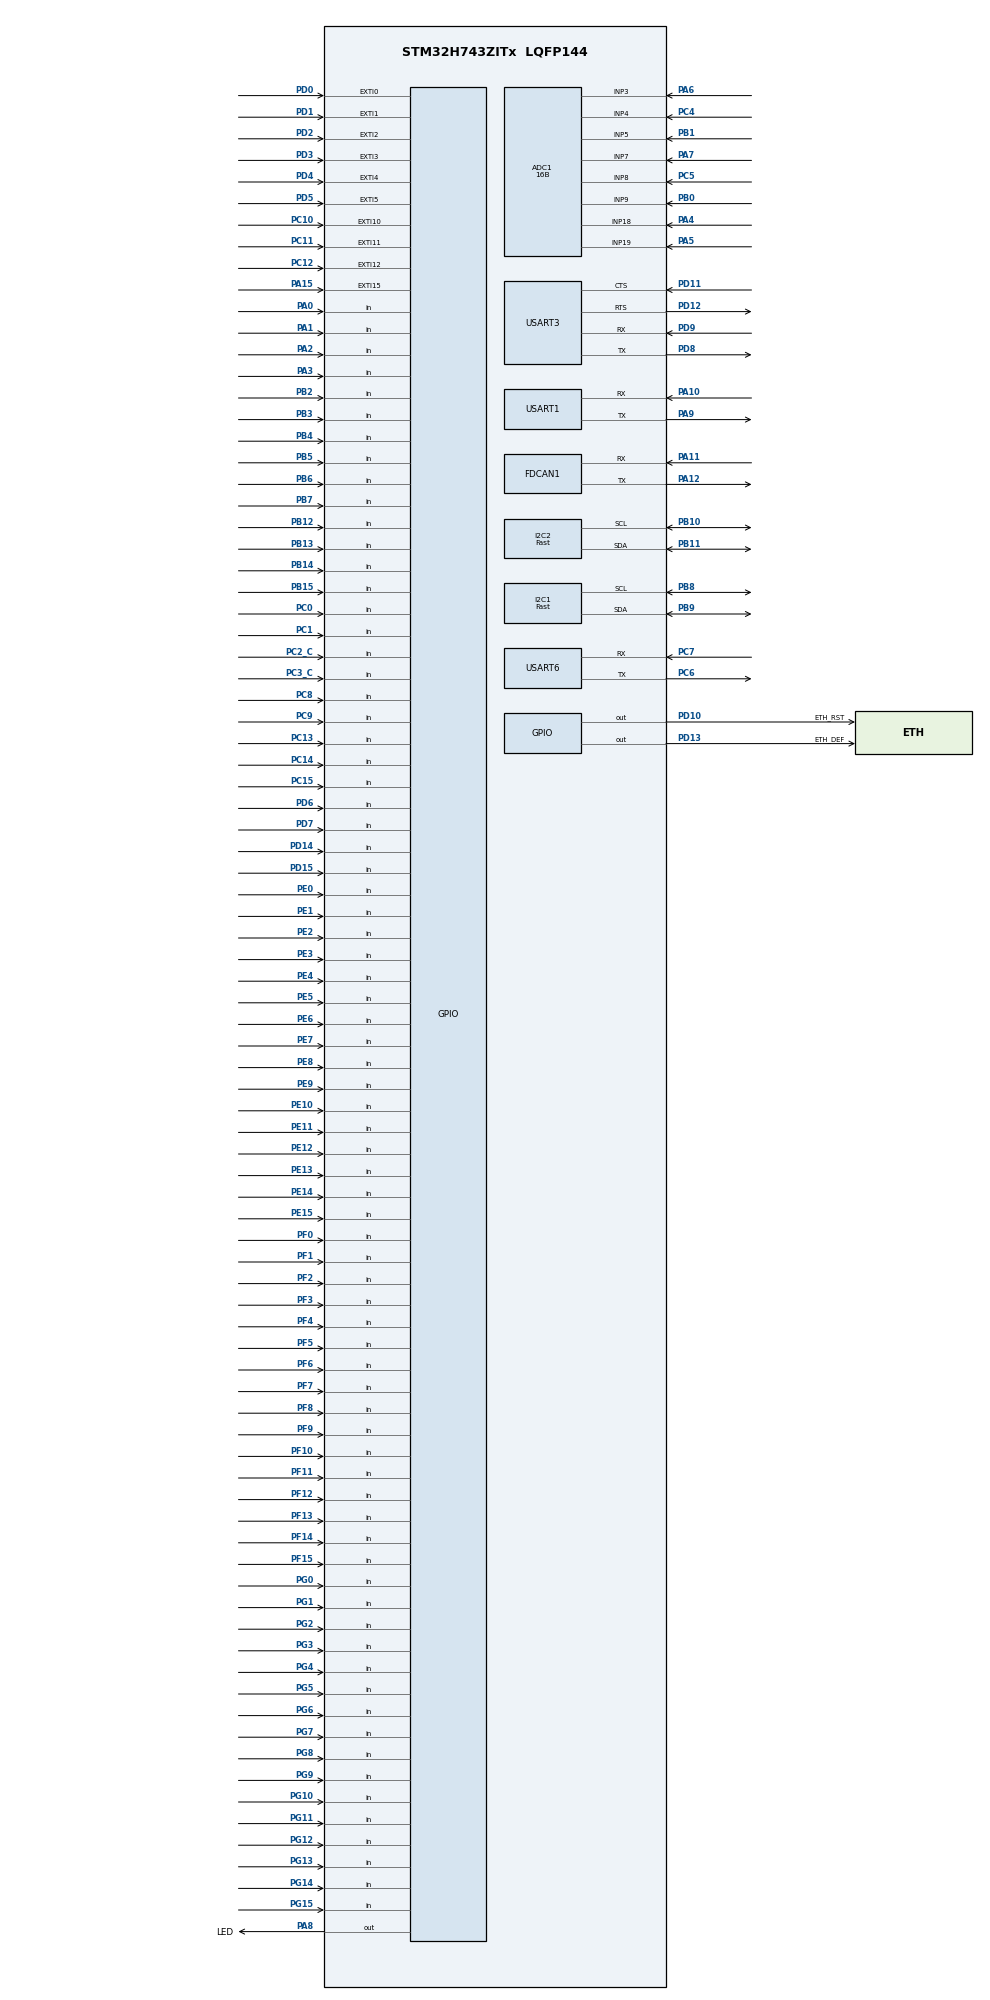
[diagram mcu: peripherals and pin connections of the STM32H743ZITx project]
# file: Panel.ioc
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ADC1.Channel-1\#ChannelRegularConversion=ADC_CHANNEL_18
ADC1.Channel-2\#ChannelRegularConversion=ADC_CHANNEL_19
ADC1.Channel-3\#ChannelRegularConversion=ADC_CHANNEL_3
ADC1.Channel-4\#ChannelRegularConversion=ADC_CHANNEL_7
ADC1.Channel-5\#ChannelRegularConversion=ADC_CHANNEL_4
ADC1.Channel-6\#ChannelRegularConversion=ADC_CHANNEL_8
ADC1.Channel-7\#ChannelRegularConversion=ADC_CHANNEL_9
ADC1.Channel-8\#ChannelRegularConversion=ADC_CHANNEL_5
ADC1.ClockPrescaler=ADC_CLOCK_ASYNC_DIV64
ADC1.ContinuousConvMode=ENABLE
ADC1.ConversionDataManagement=ADC_CONVERSIONDATA_DMA_CIRCULAR
ADC1.EOCSelection=ADC_EOC_SEQ_CONV
ADC1.NbrOfConversion=8
ADC1.NbrOfConversionFlag=1
ADC1.OffsetNumber-1\#ChannelRegularConversion=ADC_OFFSET_NONE
ADC1.OffsetNumber-2\#ChannelRegularConversion=ADC_OFFSET_NONE
ADC1.OffsetNumber-3\#ChannelRegularConversion=ADC_OFFSET_NONE
ADC1.OffsetNumber-4\#ChannelRegularConversion=ADC_OFFSET_NONE
ADC1.OffsetNumber-5\#ChannelRegularConversion=ADC_OFFSET_NONE
ADC1.OffsetNumber-6\#ChannelRegularConversion=ADC_OFFSET_NONE
ADC1.OffsetNumber-7\#ChannelRegularConversion=ADC_OFFSET_NONE
ADC1.OffsetNumber-8\#ChannelRegularConversion=ADC_OFFSET_NONE
ADC1.OffsetSignedSaturation-1\#ChannelRegularConversion=DISABLE
ADC1.OffsetSignedSaturation-2\#ChannelRegularConversion=DISABLE
ADC1.OffsetSignedSaturation-3\#ChannelRegularConversion=DISABLE
ADC1.OffsetSignedSaturation-4\#ChannelRegularConversion=DISABLE
ADC1.OffsetSignedSaturation-5\#ChannelRegularConversion=DISABLE
ADC1.OffsetSignedSaturation-6\#ChannelRegularConversion=DISABLE
ADC1.OffsetSignedSaturation-7\#ChannelRegularConversion=DISABLE
ADC1.OffsetSignedSaturation-8\#ChannelRegularConversion=DISABLE
ADC1.Rank-1\#ChannelRegularConversion=1
ADC1.Rank-2\#ChannelRegularConversion=2
ADC1.Rank-3\#ChannelRegularConversion=3
ADC1.Rank-4\#ChannelRegularConversion=4
ADC1.Rank-5\#ChannelRegularConversion=5
ADC1.Rank-6\#ChannelRegularConversion=6
ADC1.Rank-7\#ChannelRegularConversion=7
ADC1.Rank-8\#ChannelRegularConversion=8
ADC1.Resolution=ADC_RESOLUTION_16B
ADC1.SamplingTime-1\#ChannelRegularConversion=ADC_SAMPLETIME_8CYCLES_5
ADC1.SamplingTime-2\#ChannelRegularConversion=ADC_SAMPLETIME_8CYCLES_5
ADC1.SamplingTime-3\#ChannelRegularConversion=ADC_SAMPLETIME_8CYCLES_5
ADC1.SamplingTime-4\#ChannelRegularConversion=ADC_SAMPLETIME_8CYCLES_5
ADC1.SamplingTime-5\#ChannelRegularConversion=ADC_SAMPLETIME_8CYCLES_5
ADC1.SamplingTime-6\#ChannelRegularConversion=ADC_SAMPLETIME_8CYCLES_5
ADC1.SamplingTime-7\#ChannelRegularConversion=ADC_SAMPLETIME_8CYCLES_5
ADC1.SamplingTime-8\#ChannelRegularConversion=ADC_SAMPLETIME_8CYCLES_5
ADC1.master=1
Dma.ADC1.0.Direction=DMA_PERIPH_TO_MEMORY
Dma.ADC1.0.EventEnable=DISABLE
Dma.ADC1.0.FIFOMode=DMA_FIFOMODE_DISABLE
Dma.ADC1.0.Instance=DMA1_Stream0
Dma.ADC1.0.MemDataAlignment=DMA_MDATAALIGN_WORD
Dma.ADC1.0.MemInc=DMA_MINC_ENABLE
Dma.ADC1.0.Mode=DMA_CIRCULAR
Dma.ADC1.0.PeriphDataAlignment=DMA_PDATAALIGN_WORD
Dma.ADC1.0.PeriphInc=DMA_PINC_DISABLE
Dma.ADC1.0.Polarity=HAL_DMAMUX_REQ_GEN_RISING
Dma.ADC1.0.Priority=DMA_PRIORITY_LOW
Dma.ADC1.0.RequestNumber=1
Dma.ADC1.0.SignalID=NONE
Dma.ADC1.0.SyncEnable=DISABLE
Dma.ADC1.0.SyncPolarity=HAL_DMAMUX_SYNC_NO_EVENT
Dma.ADC1.0.SyncRequestNumber=1
Dma.ADC1.0.SyncSignalID=NONE
Dma.Request0=ADC1
I2C1.I2C_Speed_Mode=I2C_Fast
I2C1.Timing=0x00B03FDB
I2C2.I2C_Speed_Mode=I2C_Fast
I2C2.Timing=0x00B03FDB
Mcu.Family=STM32H7
Mcu.Name=STM32H743ZITx
Mcu.Package=LQFP144
NVIC.DMA1_Stream0_IRQn=true\:0\:0\:false\:false\:true\:false\:true
NVIC.EXTI0_IRQn=true\:0\:0\:false\:false\:true\:true\:true
NVIC.EXTI15_10_IRQn=true\:0\:0\:false\:false\:true\:true\:true
NVIC.EXTI1_IRQn=true\:0\:0\:false\:false\:true\:true\:true
NVIC.EXTI2_IRQn=true\:0\:0\:false\:false\:true\:true\:true
NVIC.EXTI3_IRQn=true\:0\:0\:false\:false\:true\:true\:true
NVIC.EXTI4_IRQn=true\:0\:0\:false\:false\:true\:true\:true
NVIC.EXTI9_5_IRQn=true\:0\:0\:false\:false\:true\:true\:true
NVIC.PriorityGroup=NVIC_PRIORITYGROUP_4
PA0.GPIO_PuPd=GPIO_PULLDOWN
PA0.Signal=GPIO_Input
PA1.GPIO_PuPd=GPIO_PULLDOWN
PA1.Signal=GPIO_Input
PA10.Mode=Asynchronous
PA10.Signal=USART1_RX
PA11.Mode=FDCANMaster
PA11.Signal=FDCAN1_RX
PA12.Mode=FDCANMaster
PA12.Signal=FDCAN1_TX
PA13\ (JTMS/SWDIO).Mode=Serial_Wire
PA13\ (JTMS/SWDIO).Signal=DEBUG_JTMS-SWDIO
PA14\ (JTCK/SWCLK).Mode=Serial_Wire
PA14\ (JTCK/SWCLK).Signal=DEBUG_JTCK-SWCLK
PA15\ (JTDI).GPIO_ModeDefaultEXTI=GPIO_MODE_IT_RISING
PA15\ (JTDI).GPIO_PuPd=GPIO_PULLDOWN
PA15\ (JTDI).Signal=GPXTI15
PA2.GPIO_PuPd=GPIO_PULLDOWN
PA2.Signal=GPIO_Input
PA3.GPIO_PuPd=GPIO_PULLDOWN
PA3.Signal=GPIO_Input
PA4.Signal=ADCx_INP18
PA5.Signal=ADCx_INP19
PA6.Signal=ADCx_INP3
PA7.Signal=ADCx_INP7
PA8.GPIO_Label=LED
PA8.Signal=GPIO_Output
PA9.Mode=Asynchronous
PA9.Signal=USART1_TX
PB0.Signal=ADCx_INP9
PB1.Signal=ADCx_INP5
PB10.Mode=I2C
PB10.Signal=I2C2_SCL
PB11.Mode=I2C
PB11.Signal=I2C2_SDA
PB12.GPIO_PuPd=GPIO_PULLDOWN
PB12.Signal=GPIO_Input
PB13.GPIO_PuPd=GPIO_PULLDOWN
PB13.Signal=GPIO_Input
PB14.GPIO_PuPd=GPIO_PULLDOWN
PB14.Signal=GPIO_Input
PB15.GPIO_PuPd=GPIO_PULLDOWN
PB15.Signal=GPIO_Input
PB2.GPIO_PuPd=GPIO_PULLDOWN
PB2.Signal=GPIO_Input
PB3\ (JTDO/TRACESWO).GPIO_PuPd=GPIO_PULLDOWN
PB3\ (JTDO/TRACESWO).Signal=GPIO_Input
PB4\ (NJTRST).GPIO_PuPd=GPIO_PULLDOWN
PB4\ (NJTRST).Signal=GPIO_Input
PB5.GPIO_PuPd=GPIO_PULLDOWN
PB5.Signal=GPIO_Input
PB6.GPIO_PuPd=GPIO_PULLDOWN
PB6.Signal=GPIO_Input
PB7.GPIO_PuPd=GPIO_PULLDOWN
PB7.Signal=GPIO_Input
PB8.Mode=I2C
PB8.Signal=I2C1_SCL
PB9.Mode=I2C
PB9.Signal=I2C1_SDA
PC0.GPIO_PuPd=GPIO_PULLDOWN
PC0.Signal=GPIO_Input
PC1.GPIO_PuPd=GPIO_PULLDOWN
PC1.Signal=GPIO_Input
PC10.GPIO_ModeDefaultEXTI=GPIO_MODE_IT_RISING
PC10.GPIO_PuPd=GPIO_PULLDOWN
PC10.Signal=GPXTI10
PC11.GPIO_ModeDefaultEXTI=GPIO_MODE_IT_RISING
PC11.GPIO_PuPd=GPIO_PULLDOWN
PC11.Signal=GPXTI11
PC12.GPIO_ModeDefaultEXTI=GPIO_MODE_IT_RISING
PC12.GPIO_PuPd=GPIO_PULLDOWN
PC12.Signal=GPXTI12
PC13.GPIO_PuPd=GPIO_PULLDOWN
PC13.Signal=GPIO_Input
PC14-OSC32_IN\ (OSC32_IN).GPIO_PuPd=GPIO_PULLDOWN
PC14-OSC32_IN\ (OSC32_IN).Signal=GPIO_Input
PC15-OSC32_OUT\ (OSC32_OUT).GPIO_PuPd=GPIO_PULLDOWN
PC15-OSC32_OUT\ (OSC32_OUT).Signal=GPIO_Input
PC2_C.GPIO_PuPd=GPIO_PULLDOWN
PC2_C.Signal=GPIO_Input
PC3_C.GPIO_PuPd=GPIO_PULLDOWN
PC3_C.Signal=GPIO_Input
PC4.Signal=ADCx_INP4
PC5.Signal=ADCx_INP8
PC6.Mode=Asynchronous
PC6.Signal=USART6_TX
PC7.Mode=Asynchronous
PC7.Signal=USART6_RX
PC8.GPIO_PuPd=GPIO_PULLDOWN
PC8.Signal=GPIO_Input
PC9.GPIO_PuPd=GPIO_PULLDOWN
PC9.Signal=GPIO_Input
PD0.GPIO_ModeDefaultEXTI=GPIO_MODE_IT_RISING
PD0.GPIO_PuPd=GPIO_PULLDOWN
PD0.Signal=GPXTI0
PD1.GPIO_ModeDefaultEXTI=GPIO_MODE_IT_RISING
PD1.GPIO_PuPd=GPIO_PULLDOWN
PD1.Signal=GPXTI1
PD10.GPIO_Label=ETH_RST
PD10.Signal=GPIO_Output
PD11.Mode=CTS_RTS
PD11.Signal=USART3_CTS
PD12.Mode=CTS_RTS
PD12.Signal=USART3_RTS
PD13.GPIO_Label=ETH_DEF
PD13.Signal=GPIO_Output
PD14.GPIO_PuPd=GPIO_PULLDOWN
PD14.Signal=GPIO_Input
PD15.GPIO_PuPd=GPIO_PULLDOWN
PD15.Signal=GPIO_Input
PD2.GPIO_ModeDefaultEXTI=GPIO_MODE_IT_RISING
PD2.GPIO_PuPd=GPIO_PULLDOWN
PD2.Signal=GPXTI2
PD3.GPIO_ModeDefaultEXTI=GPIO_MODE_IT_RISING
PD3.GPIO_PuPd=GPIO_PULLDOWN
PD3.Signal=GPXTI3
PD4.GPIO_ModeDefaultEXTI=GPIO_MODE_IT_RISING
PD4.GPIO_PuPd=GPIO_PULLDOWN
PD4.Signal=GPXTI4
PD5.GPIO_ModeDefaultEXTI=GPIO_MODE_IT_RISING
PD5.GPIO_PuPd=GPIO_PULLDOWN
PD5.Signal=GPXTI5
PD6.GPIO_PuPd=GPIO_PULLDOWN
PD6.Signal=GPIO_Input
PD7.GPIO_PuPd=GPIO_PULLDOWN
PD7.Signal=GPIO_Input
PD8.Mode=Asynchronous
PD8.Signal=USART3_TX
PD9.Mode=Asynchronous
PD9.Signal=USART3_RX
PE0.GPIO_PuPd=GPIO_PULLDOWN
PE0.Signal=GPIO_Input
PE1.GPIO_PuPd=GPIO_PULLDOWN
PE1.Signal=GPIO_Input
PE10.GPIO_PuPd=GPIO_PULLDOWN
PE10.Signal=GPIO_Input
PE11.GPIO_PuPd=GPIO_PULLDOWN
PE11.Signal=GPIO_Input
PE12.GPIO_PuPd=GPIO_PULLDOWN
PE12.Signal=GPIO_Input
PE13.GPIO_PuPd=GPIO_PULLDOWN
PE13.Signal=GPIO_Input
PE14.GPIO_PuPd=GPIO_PULLDOWN
PE14.Signal=GPIO_Input
PE15.GPIO_PuPd=GPIO_PULLDOWN
PE15.Signal=GPIO_Input
PE2.GPIO_PuPd=GPIO_PULLDOWN
PE2.Signal=GPIO_Input
PE3.GPIO_PuPd=GPIO_PULLDOWN
PE3.Signal=GPIO_Input
PE4.GPIO_PuPd=GPIO_PULLDOWN
PE4.Signal=GPIO_Input
PE5.GPIO_PuPd=GPIO_PULLDOWN
PE5.Signal=GPIO_Input
PE6.GPIO_PuPd=GPIO_PULLDOWN
PE6.Signal=GPIO_Input
PE7.GPIO_PuPd=GPIO_PULLDOWN
PE7.Signal=GPIO_Input
PE8.GPIO_PuPd=GPIO_PULLDOWN
PE8.Signal=GPIO_Input
PE9.GPIO_PuPd=GPIO_PULLDOWN
PE9.Signal=GPIO_Input
PF0.GPIO_PuPd=GPIO_PULLDOWN
PF0.Signal=GPIO_Input
PF1.GPIO_PuPd=GPIO_PULLDOWN
PF1.Signal=GPIO_Input
PF10.GPIO_PuPd=GPIO_PULLDOWN
PF10.Signal=GPIO_Input
PF11.GPIO_PuPd=GPIO_PULLDOWN
PF11.Signal=GPIO_Input
PF12.GPIO_PuPd=GPIO_PULLDOWN
PF12.Signal=GPIO_Input
PF13.GPIO_PuPd=GPIO_PULLDOWN
PF13.Signal=GPIO_Input
PF14.GPIO_PuPd=GPIO_PULLDOWN
PF14.Signal=GPIO_Input
PF15.GPIO_PuPd=GPIO_PULLDOWN
PF15.Signal=GPIO_Input
PF2.GPIO_PuPd=GPIO_PULLDOWN
PF2.Signal=GPIO_Input
PF3.GPIO_PuPd=GPIO_PULLDOWN
PF3.Signal=GPIO_Input
PF4.GPIO_PuPd=GPIO_PULLDOWN
PF4.Signal=GPIO_Input
PF5.GPIO_PuPd=GPIO_PULLDOWN
PF5.Signal=GPIO_Input
PF6.GPIO_PuPd=GPIO_PULLDOWN
PF6.Signal=GPIO_Input
PF7.GPIO_PuPd=GPIO_PULLDOWN
PF7.Signal=GPIO_Input
PF8.GPIO_PuPd=GPIO_PULLDOWN
PF8.Signal=GPIO_Input
PF9.GPIO_PuPd=GPIO_PULLDOWN
PF9.Signal=GPIO_Input
PG0.GPIO_PuPd=GPIO_PULLDOWN
PG0.Signal=GPIO_Input
PG1.GPIO_PuPd=GPIO_PULLDOWN
PG1.Signal=GPIO_Input
PG10.GPIO_PuPd=GPIO_PULLDOWN
PG10.Signal=GPIO_Input
PG11.GPIO_PuPd=GPIO_PULLDOWN
PG11.Signal=GPIO_Input
PG12.GPIO_PuPd=GPIO_PULLDOWN
PG12.Signal=GPIO_Input
PG13.GPIO_PuPd=GPIO_PULLDOWN
PG13.Signal=GPIO_Input
PG14.GPIO_PuPd=GPIO_PULLDOWN
PG14.Signal=GPIO_Input
PG15.GPIO_PuPd=GPIO_PULLDOWN
PG15.Signal=GPIO_Input
PG2.GPIO_PuPd=GPIO_PULLDOWN
PG2.Signal=GPIO_Input
PG3.GPIO_PuPd=GPIO_PULLDOWN
PG3.Signal=GPIO_Input
PG4.GPIO_PuPd=GPIO_PULLDOWN
PG4.Signal=GPIO_Input
PG5.GPIO_PuPd=GPIO_PULLDOWN
PG5.Signal=GPIO_Input
PG6.GPIO_PuPd=GPIO_PULLDOWN
PG6.Signal=GPIO_Input
PG7.GPIO_PuPd=GPIO_PULLDOWN
PG7.Signal=GPIO_Input
PG8.GPIO_PuPd=GPIO_PULLDOWN
PG8.Signal=GPIO_Input
PG9.GPIO_PuPd=GPIO_PULLDOWN
PG9.Signal=GPIO_Input
PH0-OSC_IN\ (PH0).Mode=HSE-External-Oscillator
PH0-OSC_IN\ (PH0).Signal=RCC_OSC_IN
PH1-OSC_OUT\ (PH1).Mode=HSE-External-Oscillator
PH1-OSC_OUT\ (PH1).Signal=RCC_OSC_OUT
ProjectManager.HeapSize=0x200
ProjectManager.StackSize=0x400
ProjectManager.TargetToolchain=STM32CubeIDE
RCC.ADCFreq_Value=150000000
RCC.APB1Freq_Value=120000000
RCC.APB2Freq_Value=120000000
RCC.APB3Freq_Value=120000000
RCC.APB4Freq_Value=120000000
RCC.CortexFreq_Value=480000000
RCC.D1PPRE=RCC_APB3_DIV2
RCC.D2PPRE1=RCC_APB1_DIV2
RCC.D2PPRE2=RCC_APB2_DIV2
RCC.D3PPRE=RCC_APB4_DIV2
RCC.DIVM1=1
RCC.DIVM2=1
RCC.DIVN1=120
RCC.DIVN2=18
RCC.DIVP2=1
RCC.DIVQ1=12
RCC.HCLKFreq_Value=240000000
RCC.HPRE=RCC_HCLK_DIV2
RCC.HSE_VALUE=8000000
RCC.PLL2FRACN=6144
RCC.PLL3FRACN=0
RCC.PLLFRACN=0
RCC.PLLSourceVirtual=RCC_PLLSOURCE_HSE
RCC.SYSCLKFreq_VALUE=480000000
RCC.SYSCLKSource=RCC_SYSCLKSOURCE_PLLCLK
RCC.USBFreq_Value=80000000
SH.ADCx_INP18.0=ADC1_INP18,IN18-Single-Ended
SH.ADCx_INP19.0=ADC1_INP19,IN19-Single-Ended
SH.ADCx_INP3.0=ADC1_INP3,IN3-Single-Ended
SH.ADCx_INP4.0=ADC1_INP4,IN4-Single-Ended
SH.ADCx_INP5.0=ADC1_INP5,IN5-Single-Ended
SH.ADCx_INP7.0=ADC1_INP7,IN7-Single-Ended
SH.ADCx_INP8.0=ADC1_INP8,IN8-Single-Ended
SH.ADCx_INP9.0=ADC1_INP9,IN9-Single-Ended
USART1.VirtualMode-Asynchronous=VM_ASYNC
USART3.VirtualMode-Asynchronous=VM_ASYNC
USART6.VirtualMode-Asynchronous=VM_ASYNC
board=custom

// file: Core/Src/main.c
/* USER CODE BEGIN Header */
/**
  ******************************************************************************
  * @file           : main.c
  * @brief          : Main program body
  ******************************************************************************
  * @attention
  *
  * <h2><center>&copy; Copyright (c) 2020 STMicroelectronics.
  * All rights reserved.</center></h2>
  *
  * This software component is licensed by ST under BSD 3-Clause license,
  * the "License"; You may not use this file except in compliance with the
  * License. You may obtain a copy of the License at:
  *                        opensource.org/licenses/BSD-3-Clause
  *
  ******************************************************************************
  */
/* USER CODE END Header */
#include "main.h"
#include "adc.h"
#include "dma.h"
#include "fdcan.h"
#include "i2c.h"
#include "usart.h"
#include "gpio.h"

/* USER CODE BEGIN Includes */
#include <stdlib.h>

#include <../Lib/kontrolka.h>
#include <../Lib/MCP23017.h>
#include <../Lib/MAX11616.h>
#include <../Lib/pins.h>
#include <../Lib/pin_master.h>
/* USER CODE END Includes */

/* USER CODE BEGIN PV */
pin_master_t *pin_master;
/* USER CODE END PV */

void SystemClock_Config(void);

int main(void)
{

  /* MCU Configuration--------------------------------------------------------*/

  /* Reset of all peripherals, Initializes the Flash interface and the Systick. */
  HAL_Init();

  /* Configure the system clock */
  SystemClock_Config();

  /* Initialize all configured peripherals */
  MX_GPIO_Init();
  MX_DMA_Init();
  MX_I2C1_Init();
  MX_I2C2_Init();
  MX_ADC1_Init();
  MX_FDCAN1_Init();
  MX_USART1_UART_Init();
  MX_USART3_UART_Init();
  MX_USART6_UART_Init();
  /* USER CODE BEGIN 2 */
  for (int i = 0; i < 256; ++i)
  {
    if (HAL_I2C_IsDeviceReady(&hi2c2, i, 1, 2) == HAL_OK)
    {
      HAL_Delay(10);
    }
  }
  pin_master = pin_master_create();
  /* USER CODE END 2 */

  /* Infinite loop */
  while (1)
  {

    /* USER CODE BEGIN 3 */
    HAL_GPIO_TogglePin(LED_GPIO_Port, LED_Pin);
    //HAL_Delay(50);
    pin_master->reload_inputs(pin_master);
    pin_master->reload_outputs(pin_master);
  }
  /* USER CODE END 3 */
}

void SystemClock_Config(void)
{
  RCC_OscInitTypeDef RCC_OscInitStruct = {0};
  RCC_ClkInitTypeDef RCC_ClkInitStruct = {0};
  RCC_PeriphCLKInitTypeDef PeriphClkInitStruct = {0};

  /** Supply configuration update enable
  */
  HAL_PWREx_ConfigSupply(PWR_LDO_SUPPLY);
  /** Configure the main internal regulator output voltage
  */
  __HAL_PWR_VOLTAGESCALING_CONFIG(PWR_REGULATOR_VOLTAGE_SCALE0);

  while(!__HAL_PWR_GET_FLAG(PWR_FLAG_VOSRDY)) {}
  /** Macro to configure the PLL clock source
  */
  __HAL_RCC_PLL_PLLSOURCE_CONFIG(RCC_PLLSOURCE_HSE);
  /** Initializes the RCC Oscillators according to the specified parameters
  * in the RCC_OscInitTypeDef structure.
  */
  RCC_OscInitStruct.OscillatorType = RCC_OSCILLATORTYPE_HSE;
  RCC_OscInitStruct.HSEState = RCC_HSE_ON;
  RCC_OscInitStruct.PLL.PLLState = RCC_PLL_ON;
  RCC_OscInitStruct.PLL.PLLSource = RCC_PLLSOURCE_HSE;
  RCC_OscInitStruct.PLL.PLLM = 1;
  RCC_OscInitStruct.PLL.PLLN = 120;
  RCC_OscInitStruct.PLL.PLLP = 2;
  RCC_OscInitStruct.PLL.PLLQ = 12;
  RCC_OscInitStruct.PLL.PLLR = 2;
  RCC_OscInitStruct.PLL.PLLRGE = RCC_PLL1VCIRANGE_3;
  RCC_OscInitStruct.PLL.PLLVCOSEL = RCC_PLL1VCOWIDE;
  RCC_OscInitStruct.PLL.PLLFRACN = 0;
  if (HAL_RCC_OscConfig(&RCC_OscInitStruct) != HAL_OK)
  {
    Error_Handler();
  }
  /** Initializes the CPU, AHB and APB buses clocks
  */
  RCC_ClkInitStruct.ClockType = RCC_CLOCKTYPE_HCLK|RCC_CLOCKTYPE_SYSCLK
                              |RCC_CLOCKTYPE_PCLK1|RCC_CLOCKTYPE_PCLK2
                              |RCC_CLOCKTYPE_D3PCLK1|RCC_CLOCKTYPE_D1PCLK1;
  RCC_ClkInitStruct.SYSCLKSource = RCC_SYSCLKSOURCE_PLLCLK;
  RCC_ClkInitStruct.SYSCLKDivider = RCC_SYSCLK_DIV1;
  RCC_ClkInitStruct.AHBCLKDivider = RCC_HCLK_DIV2;
  RCC_ClkInitStruct.APB3CLKDivider = RCC_APB3_DIV2;
  RCC_ClkInitStruct.APB1CLKDivider = RCC_APB1_DIV2;
  RCC_ClkInitStruct.APB2CLKDivider = RCC_APB2_DIV2;
  RCC_ClkInitStruct.APB4CLKDivider = RCC_APB4_DIV2;

  if (HAL_RCC_ClockConfig(&RCC_ClkInitStruct, FLASH_LATENCY_4) != HAL_OK)
  {
    Error_Handler();
  }
  PeriphClkInitStruct.PeriphClockSelection = RCC_PERIPHCLK_USART3|RCC_PERIPHCLK_USART6
                              |RCC_PERIPHCLK_FDCAN|RCC_PERIPHCLK_USART1
                              |RCC_PERIPHCLK_I2C2|RCC_PERIPHCLK_ADC
                              |RCC_PERIPHCLK_I2C1;
  PeriphClkInitStruct.PLL2.PLL2M = 1;
  PeriphClkInitStruct.PLL2.PLL2N = 18;
  PeriphClkInitStruct.PLL2.PLL2P = 1;
  PeriphClkInitStruct.PLL2.PLL2Q = 2;
  PeriphClkInitStruct.PLL2.PLL2R = 2;
  PeriphClkInitStruct.PLL2.PLL2RGE = RCC_PLL2VCIRANGE_3;
  PeriphClkInitStruct.PLL2.PLL2VCOSEL = RCC_PLL2VCOMEDIUM;
  PeriphClkInitStruct.PLL2.PLL2FRACN = 6144;
  PeriphClkInitStruct.FdcanClockSelection = RCC_FDCANCLKSOURCE_PLL;
  PeriphClkInitStruct.Usart234578ClockSelection = RCC_USART234578CLKSOURCE_D2PCLK1;
  PeriphClkInitStruct.Usart16ClockSelection = RCC_USART16CLKSOURCE_D2PCLK2;
  PeriphClkInitStruct.I2c123ClockSelection = RCC_I2C123CLKSOURCE_D2PCLK1;
  PeriphClkInitStruct.AdcClockSelection = RCC_ADCCLKSOURCE_PLL2;
  if (HAL_RCCEx_PeriphCLKConfig(&PeriphClkInitStruct) != HAL_OK)
  {
    Error_Handler();
  }
}

void Error_Handler(void)
{
}

/************************ (C) COPYRIGHT STMicroelectronics *****END OF FILE****/
